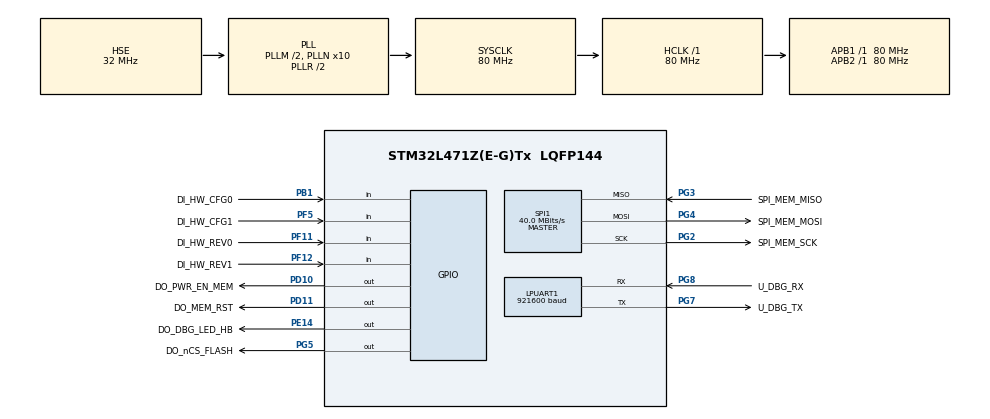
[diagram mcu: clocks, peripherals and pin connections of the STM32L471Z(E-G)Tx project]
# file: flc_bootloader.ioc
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IWDG.Prescaler=IWDG_PRESCALER_16
LPUART1.BaudRate=921600
LPUART1.WordLength=UART_WORDLENGTH_8B
Mcu.Family=STM32L4
Mcu.Name=STM32L471Z(E-G)Tx
Mcu.Package=LQFP144
NVIC.LPUART1_IRQn=true\:0\:0\:false\:false\:true\:true\:true
NVIC.PriorityGroup=NVIC_PRIORITYGROUP_4
NVIC.SPI1_IRQn=true\:0\:0\:false\:false\:true\:true\:true
NVIC.TIM1_UP_TIM16_IRQn=true\:0\:0\:false\:false\:true\:false\:true
NVIC.TimeBase=TIM1_UP_TIM16_IRQn
NVIC.TimeBaseIP=TIM16
PA13\ (JTMS-SWDIO).GPIO_Label=SWDIO
PA13\ (JTMS-SWDIO).Mode=Serial_Wire
PA13\ (JTMS-SWDIO).Signal=SYS_JTMS-SWDIO
PA14\ (JTCK-SWCLK).GPIO_Label=SWCLK
PA14\ (JTCK-SWCLK).Mode=Serial_Wire
PA14\ (JTCK-SWCLK).Signal=SYS_JTCK-SWCLK
PB1.GPIO_Label=DI_HW_CFG0
PB1.Signal=GPIO_Input
PC14-OSC32_IN\ (PC14).Mode=LSE-External-Oscillator
PC14-OSC32_IN\ (PC14).Signal=RCC_OSC32_IN
PC15-OSC32_OUT\ (PC15).Mode=LSE-External-Oscillator
PC15-OSC32_OUT\ (PC15).Signal=RCC_OSC32_OUT
PD10.GPIO_Label=DO_PWR_EN_MEM
PD10.PinState=GPIO_PIN_RESET
PD10.Signal=GPIO_Output
PD11.GPIO_Label=DO_MEM_RST
PD11.PinState=GPIO_PIN_SET
PD11.Signal=GPIO_Output
PE14.GPIO_Label=DO_DBG_LED_HB
PE14.Signal=GPIO_Output
PF11.GPIO_Label=DI_HW_REV0
PF11.Signal=GPIO_Input
PF12.GPIO_Label=DI_HW_REV1
PF12.Signal=GPIO_Input
PF5.GPIO_Label=DI_HW_CFG1
PF5.Signal=GPIO_Input
PG2.GPIO_Label=SPI_MEM_SCK
PG2.Mode=Full_Duplex_Master
PG2.Signal=SPI1_SCK
PG3.GPIO_Label=SPI_MEM_MISO
PG3.Mode=Full_Duplex_Master
PG3.Signal=SPI1_MISO
PG4.GPIO_Label=SPI_MEM_MOSI
PG4.Mode=Full_Duplex_Master
PG4.Signal=SPI1_MOSI
PG5.GPIO_Label=DO_nCS_FLASH
PG5.PinState=GPIO_PIN_SET
PG5.Signal=GPIO_Output
PG7.GPIO_Label=U_DBG_TX
PG7.Mode=Asynchronous
PG7.Signal=LPUART1_TX
PG8.GPIO_Label=U_DBG_RX
PG8.GPIO_PuPd=GPIO_PULLUP
PG8.Mode=Asynchronous
PG8.Signal=LPUART1_RX
PH0-OSC_IN\ (PH0).Mode=HSE-External-Oscillator
PH0-OSC_IN\ (PH0).Signal=RCC_OSC_IN
PH1-OSC_OUT\ (PH1).Mode=HSE-External-Oscillator
PH1-OSC_OUT\ (PH1).Signal=RCC_OSC_OUT
ProjectManager.HeapSize=0x00
ProjectManager.StackSize=0x1000
ProjectManager.TargetToolchain=MDK-ARM V5.27
RCC.ADCFreq_Value=64000000
RCC.AHBFreq_Value=80000000
RCC.APB1Freq_Value=80000000
RCC.APB1TimFreq_Value=80000000
RCC.APB2Freq_Value=80000000
RCC.APB2TimFreq_Value=80000000
RCC.CortexFreq_Value=80000000
RCC.HCLKFreq_Value=80000000
RCC.HSE_VALUE=32000000
RCC.HSI_VALUE=16000000
RCC.MSI_VALUE=4000000
RCC.PLLM=2
RCC.PLLN=10
RCC.PLLSourceVirtual=RCC_PLLSOURCE_HSE
RCC.RTCClockSelection=RCC_RTCCLKSOURCE_LSE
RCC.SYSCLKFreq_VALUE=80000000
RCC.SYSCLKSource=RCC_SYSCLKSOURCE_PLLCLK
RCC.VCOOutputFreq_Value=160000000
SPI1.BaudRatePrescaler=SPI_BAUDRATEPRESCALER_2
SPI1.CalculateBaudRate=40.0 MBits/s
SPI1.DataSize=SPI_DATASIZE_8BIT
SPI1.Direction=SPI_DIRECTION_2LINES
SPI1.Mode=SPI_MODE_MASTER
SPI1.VirtualType=VM_MASTER
VP_IWDG_VS_IWDG.Mode=IWDG_Activate
VP_RTC_VS_RTC_Activate.Mode=RTC_Enabled
VP_SYS_VS_tim16.Mode=TIM16
board=custom

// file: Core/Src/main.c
/* USER CODE BEGIN Header */
/**
  ******************************************************************************
  * @file           : main.c
  * @brief          : Main program body
  ******************************************************************************
  * @attention
  *
  * <h2><center>&copy; Copyright (c) 2021 STMicroelectronics.
  * All rights reserved.</center></h2>
  *
  * This software component is licensed by ST under BSD 3-Clause license,
  * the "License"; You may not use this file except in compliance with the
  * License. You may obtain a copy of the License at:
  *                        opensource.org/licenses/BSD-3-Clause
  *
  ******************************************************************************
  */
/* USER CODE END Header */
#include "main.h"

/* USER CODE BEGIN Includes */
#include <hal/hal.h>
#include <plf/plf.h>
#include <plf/blc/blc.h>
#include <plf/evos/evos.h>
#include <bapp/bapp.h>
/* USER CODE END Includes */

IWDG_HandleTypeDef hiwdg;

UART_HandleTypeDef hlpuart1;

RTC_HandleTypeDef hrtc;

SPI_HandleTypeDef hspi1;

void SystemClock_Config(void);
static void MX_GPIO_Init(void);
static void MX_LPUART1_UART_Init(void);
static void MX_SPI1_Init(void);
static void MX_RTC_Init(void);

int main(void)
{

  /* MCU Configuration--------------------------------------------------------*/

  /* Reset of all peripherals, Initializes the Flash interface and the Systick. */
  HAL_Init();

  /* USER CODE BEGIN Init */
	pBootControl->rccCsr = RCC->CSR;
  __HAL_RCC_CLEAR_RESET_FLAGS();
  /* USER CODE END Init */

  /* Configure the system clock */
  SystemClock_Config();

  /* Initialize all configured peripherals */
  MX_GPIO_Init();
  MX_LPUART1_UART_Init();
  MX_SPI1_Init();
  MX_RTC_Init();
  /* USER CODE BEGIN 2 */
  HalInterruptEnable(NULL);
  EvosInit();
  HalInit();
	PlfInit();

  BAPP_Init();  // Last called before Evos Start
  /* USER CODE END 2 */

  /* Infinite loop */
  /* USER CODE BEGIN WHILE */
  EvosSchedulerStart(NULL);
    /* USER CODE END WHILE */

}

void SystemClock_Config(void)
{
  RCC_OscInitTypeDef RCC_OscInitStruct = {0};
  RCC_ClkInitTypeDef RCC_ClkInitStruct = {0};

  /** Configure the main internal regulator output voltage
  */
  if (HAL_PWREx_ControlVoltageScaling(PWR_REGULATOR_VOLTAGE_SCALE1) != HAL_OK)
  {
    Error_Handler();
  }
  /** Configure LSE Drive Capability
  */
  HAL_PWR_EnableBkUpAccess();
  __HAL_RCC_LSEDRIVE_CONFIG(RCC_LSEDRIVE_LOW);
  /** Initializes the RCC Oscillators according to the specified parameters
  * in the RCC_OscInitTypeDef structure.
  */
  RCC_OscInitStruct.OscillatorType = RCC_OSCILLATORTYPE_LSI|RCC_OSCILLATORTYPE_HSE
                              |RCC_OSCILLATORTYPE_LSE;
  RCC_OscInitStruct.HSEState = RCC_HSE_ON;
  RCC_OscInitStruct.LSEState = RCC_LSE_ON;
  RCC_OscInitStruct.LSIState = RCC_LSI_ON;
  RCC_OscInitStruct.PLL.PLLState = RCC_PLL_ON;
  RCC_OscInitStruct.PLL.PLLSource = RCC_PLLSOURCE_HSE;
  RCC_OscInitStruct.PLL.PLLM = 2;
  RCC_OscInitStruct.PLL.PLLN = 10;
  RCC_OscInitStruct.PLL.PLLP = RCC_PLLP_DIV7;
  RCC_OscInitStruct.PLL.PLLQ = RCC_PLLQ_DIV2;
  RCC_OscInitStruct.PLL.PLLR = RCC_PLLR_DIV2;
  if (HAL_RCC_OscConfig(&RCC_OscInitStruct) != HAL_OK)
  {
    Error_Handler();
  }
  /** Initializes the CPU, AHB and APB buses clocks
  */
  RCC_ClkInitStruct.ClockType = RCC_CLOCKTYPE_HCLK|RCC_CLOCKTYPE_SYSCLK
                              |RCC_CLOCKTYPE_PCLK1|RCC_CLOCKTYPE_PCLK2;
  RCC_ClkInitStruct.SYSCLKSource = RCC_SYSCLKSOURCE_PLLCLK;
  RCC_ClkInitStruct.AHBCLKDivider = RCC_SYSCLK_DIV1;
  RCC_ClkInitStruct.APB1CLKDivider = RCC_HCLK_DIV1;
  RCC_ClkInitStruct.APB2CLKDivider = RCC_HCLK_DIV1;

  if (HAL_RCC_ClockConfig(&RCC_ClkInitStruct, FLASH_LATENCY_4) != HAL_OK)
  {
    Error_Handler();
  }
}

void MX_IWDG_Init(void)
{

  hiwdg.Instance = IWDG;
  hiwdg.Init.Prescaler = IWDG_PRESCALER_16;
  hiwdg.Init.Window = 4095;
  hiwdg.Init.Reload = 4095;
  if (HAL_IWDG_Init(&hiwdg) != HAL_OK)
  {
    Error_Handler();
  }

}

static void MX_LPUART1_UART_Init(void)
{

  hlpuart1.Instance = LPUART1;
  hlpuart1.Init.BaudRate = 921600;
  hlpuart1.Init.WordLength = UART_WORDLENGTH_8B;
  hlpuart1.Init.StopBits = UART_STOPBITS_1;
  hlpuart1.Init.Parity = UART_PARITY_NONE;
  hlpuart1.Init.Mode = UART_MODE_TX_RX;
  hlpuart1.Init.HwFlowCtl = UART_HWCONTROL_NONE;
  hlpuart1.Init.OneBitSampling = UART_ONE_BIT_SAMPLE_DISABLE;
  hlpuart1.AdvancedInit.AdvFeatureInit = UART_ADVFEATURE_NO_INIT;
  if (HAL_UART_Init(&hlpuart1) != HAL_OK)
  {
    Error_Handler();
  }

}

static void MX_RTC_Init(void)
{

  /** Initialize RTC Only
  */
  hrtc.Instance = RTC;
  hrtc.Init.HourFormat = RTC_HOURFORMAT_24;
  hrtc.Init.AsynchPrediv = 127;
  hrtc.Init.SynchPrediv = 255;
  hrtc.Init.OutPut = RTC_OUTPUT_DISABLE;
  hrtc.Init.OutPutRemap = RTC_OUTPUT_REMAP_NONE;
  hrtc.Init.OutPutPolarity = RTC_OUTPUT_POLARITY_HIGH;
  hrtc.Init.OutPutType = RTC_OUTPUT_TYPE_OPENDRAIN;
  if (HAL_RTC_Init(&hrtc) != HAL_OK)
  {
    Error_Handler();
  }

}

static void MX_SPI1_Init(void)
{

  /* SPI1 parameter configuration*/
  hspi1.Instance = SPI1;
  hspi1.Init.Mode = SPI_MODE_MASTER;
  hspi1.Init.Direction = SPI_DIRECTION_2LINES;
  hspi1.Init.DataSize = SPI_DATASIZE_8BIT;
  hspi1.Init.CLKPolarity = SPI_POLARITY_LOW;
  hspi1.Init.CLKPhase = SPI_PHASE_1EDGE;
  hspi1.Init.NSS = SPI_NSS_SOFT;
  hspi1.Init.BaudRatePrescaler = SPI_BAUDRATEPRESCALER_2;
  hspi1.Init.FirstBit = SPI_FIRSTBIT_MSB;
  hspi1.Init.TIMode = SPI_TIMODE_DISABLE;
  hspi1.Init.CRCCalculation = SPI_CRCCALCULATION_DISABLE;
  hspi1.Init.CRCPolynomial = 7;
  hspi1.Init.CRCLength = SPI_CRC_LENGTH_DATASIZE;
  hspi1.Init.NSSPMode = SPI_NSS_PULSE_ENABLE;
  if (HAL_SPI_Init(&hspi1) != HAL_OK)
  {
    Error_Handler();
  }

}

static void MX_GPIO_Init(void)
{
  GPIO_InitTypeDef GPIO_InitStruct = {0};

  /* GPIO Ports Clock Enable */
  __HAL_RCC_GPIOC_CLK_ENABLE();
  __HAL_RCC_GPIOF_CLK_ENABLE();
  __HAL_RCC_GPIOH_CLK_ENABLE();
  __HAL_RCC_GPIOB_CLK_ENABLE();
  __HAL_RCC_GPIOE_CLK_ENABLE();
  __HAL_RCC_GPIOD_CLK_ENABLE();
  __HAL_RCC_GPIOG_CLK_ENABLE();
  HAL_PWREx_EnableVddIO2();
  __HAL_RCC_GPIOA_CLK_ENABLE();

  /*Configure GPIO pin Output Level */
  HAL_GPIO_WritePin(DO_DBG_LED_HB_GPIO_Port, DO_DBG_LED_HB_Pin, GPIO_PIN_RESET);

  /*Configure GPIO pin Output Level */
  HAL_GPIO_WritePin(DO_PWR_EN_MEM_GPIO_Port, DO_PWR_EN_MEM_Pin, GPIO_PIN_RESET);

  /*Configure GPIO pin Output Level */
  HAL_GPIO_WritePin(DO_MEM_RST_GPIO_Port, DO_MEM_RST_Pin, GPIO_PIN_SET);

  /*Configure GPIO pin Output Level */
  HAL_GPIO_WritePin(DO_nCS_FLASH_GPIO_Port, DO_nCS_FLASH_Pin, GPIO_PIN_SET);

  /*Configure GPIO pins : DI_HW_CFG1_Pin DI_HW_REV0_Pin DI_HW_REV1_Pin */
  GPIO_InitStruct.Pin = DI_HW_CFG1_Pin|DI_HW_REV0_Pin|DI_HW_REV1_Pin;
  GPIO_InitStruct.Mode = GPIO_MODE_INPUT;
  GPIO_InitStruct.Pull = GPIO_NOPULL;
  HAL_GPIO_Init(GPIOF, &GPIO_InitStruct);

  /*Configure GPIO pin : DI_HW_CFG0_Pin */
  GPIO_InitStruct.Pin = DI_HW_CFG0_Pin;
  GPIO_InitStruct.Mode = GPIO_MODE_INPUT;
  GPIO_InitStruct.Pull = GPIO_NOPULL;
  HAL_GPIO_Init(DI_HW_CFG0_GPIO_Port, &GPIO_InitStruct);

  /*Configure GPIO pin : DO_DBG_LED_HB_Pin */
  GPIO_InitStruct.Pin = DO_DBG_LED_HB_Pin;
  GPIO_InitStruct.Mode = GPIO_MODE_OUTPUT_PP;
  GPIO_InitStruct.Pull = GPIO_NOPULL;
  GPIO_InitStruct.Speed = GPIO_SPEED_FREQ_LOW;
  HAL_GPIO_Init(DO_DBG_LED_HB_GPIO_Port, &GPIO_InitStruct);

  /*Configure GPIO pins : DO_PWR_EN_MEM_Pin DO_MEM_RST_Pin */
  GPIO_InitStruct.Pin = DO_PWR_EN_MEM_Pin|DO_MEM_RST_Pin;
  GPIO_InitStruct.Mode = GPIO_MODE_OUTPUT_PP;
  GPIO_InitStruct.Pull = GPIO_NOPULL;
  GPIO_InitStruct.Speed = GPIO_SPEED_FREQ_LOW;
  HAL_GPIO_Init(GPIOD, &GPIO_InitStruct);

  /*Configure GPIO pin : DO_nCS_FLASH_Pin */
  GPIO_InitStruct.Pin = DO_nCS_FLASH_Pin;
  GPIO_InitStruct.Mode = GPIO_MODE_OUTPUT_PP;
  GPIO_InitStruct.Pull = GPIO_NOPULL;
  GPIO_InitStruct.Speed = GPIO_SPEED_FREQ_LOW;
  HAL_GPIO_Init(DO_nCS_FLASH_GPIO_Port, &GPIO_InitStruct);

}

void HAL_TIM_PeriodElapsedCallback(TIM_HandleTypeDef *htim)
{
  if (htim->Instance == TIM16) {
    HAL_IncTick();
  }
}

void Error_Handler(void)
{
  __disable_irq();
  while (1)
  {
  }
}
